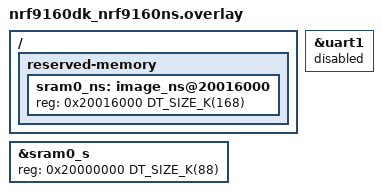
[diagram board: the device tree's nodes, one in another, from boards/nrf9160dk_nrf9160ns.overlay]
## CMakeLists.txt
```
#
# Copyright (c) 2021 Linaro Limited
#
# SPDX-License-Identifier: Apache-2.0
#

# Building TFM requires Cmake 3.15.
cmake_minimum_required(VERSION 3.15)

find_package(Zephyr REQUIRED HINTS $ENV{ZEPHYR_BASE})

project(psa_custom_service)

target_sources(app PRIVATE src/main.c)
target_sources(app PRIVATE src/util_app_log.c)
target_sources(app PRIVATE src/util_sformat.c)

target_include_directories(app PRIVATE
  ${ZEPHYR_TRUSTED_FIRMWARE_M_MODULE_DIR}/trusted-firmware-m/interface/include
)

# In TF-M, for release build, all the logs are silenced. At least enable
# `LOG_LEVEL_INFO`
set_property(TARGET zephyr_property_target
             APPEND PROPERTY TFM_CMAKE_OPTIONS
             -DTFM_SPM_LOG_LEVEL=TFM_SPM_LOG_LEVEL_INFO
             -DTFM_PARTITION_LOG_LEVEL=TFM_PARTITION_LOG_LEVEL_INFO
)
```

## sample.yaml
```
sample:
  description: PSA Custom Service sample
  name: PSA Custom Service
tests:
    sample.psa_custom_service:
        tags: introduction tfm psa custom service
        platform_allow: mps2_an521_nonsecure lpcxpresso55s69_ns nrf5340dk_nrf5340_cpuappns
          nrf9160dk_nrf9160ns nucleo_l552ze_q_ns v2m_musca_s1_nonsecure stm32l562e_dk_ns
          bl5340_dvk_cpuappns
        harness: console
        harness_config:
          type: multi_line
          regex:
            - "app: Hashing the message"
            - "\\[Example partition\\] Calculating SHA-256 hash!"
            - "\\[Example partition\\] Done!"
            - "app: Size of SHA-256 hash is 32 bytes"
```

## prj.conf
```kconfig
#
# Copyright (c) 2021 Linaro Limited
#
# SPDX-License-Identifier: Apache-2.0
#

CONFIG_LOG=y
CONFIG_LOG_RUNTIME_FILTERING=y
CONFIG_LOG_BUFFER_SIZE=2048
CONFIG_LOG_PROCESS_TRIGGER_THRESHOLD=0
CONFIG_LOG_DEFAULT_LEVEL=4

CONFIG_BUILD_WITH_TFM=y
CONFIG_TFM_IPC=y
CONFIG_TFM_PARTITION_EXAMPLE=y
# CONFIG_TFM_ISOLATION_LEVEL=3
# CONFIG_TFM_BL2=y
# CONFIG_TFM_CMAKE_BUILD_TYPE_DEBUG=y

# The Zephyr CMSIS emulation assumes that ticks are ms, currently
CONFIG_SYS_CLOCK_TICKS_PER_SEC=1000

CONFIG_MAIN_STACK_SIZE=4096
CONFIG_HEAP_MEM_POOL_SIZE=4096
```

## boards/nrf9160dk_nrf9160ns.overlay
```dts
/*
 * Copyright (c) 2020 Nordic Semiconductor ASA.
 *
 * SPDX-License-Identifier: Apache-2.0
 */

/* Modify the SRAM partitioning to accommodate the requirements
 * for the Secure (TF-M) firmware for the configuration that is
 * used in this sample.
 */

/* Increase the size of the Secure Firmware (TF-M).
 * This modification is not required at the moment,
 * since TF-M region definitions are configured
 * statically in the TF-M project.
 */
&sram0_s {
	reg = <0x20000000 DT_SIZE_K(88)>;
};

/* Decrease the size of the Non-Secure Firmware (Zephyr),
 * and move its starting address to the offset expected by
 * TF-M.
 */
/delete-node/ &sram0_ns;
/ {
	reserved-memory {
		sram0_ns: image_ns@20016000 {
			reg = <0x20016000 DT_SIZE_K(168)>;
		};
	};
};

/* Disable UART1, because it is used by default in TF-M */
&uart1 {
	status = "disabled";
};
```

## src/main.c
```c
/*
 * Copyright (c) 2021 Linaro Limited
 *
 * SPDX-License-Identifier: Apache-2.0
 */

#include <zephyr.h>
#include <logging/log_ctrl.h>
#include <logging/log.h>

#include "tfm_example_partition_api.h"
#include "util_app_log.h"
#include "util_sformat.h"

/** Declare a reference to the application logging interface. */
LOG_MODULE_DECLARE(app, CONFIG_LOG_DEFAULT_LEVEL);

struct sf_hex_tbl_fmt main_fmt = {
	.ascii = true,
	.addr_label = true,
	.addr = 0
};

void main(void)
{
	/* Message to be hashed */
	uint8_t input[] = "Please hash this message.";
	uint8_t hash[PSA_HASH_SIZE(PSA_ALG_SHA_256)] = { 0 };
	size_t hash_len;
	psa_status_t status;

	/* Initialise the logger subsys and dump the current buffer. */
	log_init();

	LOG_INF("Hashing the message");
	al_dump_log();

	/* Display the message */
	sf_hex_tabulate_16(&main_fmt, input, strlen(input));

	status = al_psa_status(
		psa_example_hash(input,
						 strlen(input),
						 hash,
						 sizeof(hash),
						 &hash_len),
		__func__);

	if (status != PSA_SUCCESS) {
		LOG_ERR("Failed to compute SHA-256 hash");
		goto err;
	}

	LOG_INF("Size of SHA-256 hash is %d bytes", hash_len);
	al_dump_log();

	/* Display the SHA-256 hash */
	sf_hex_tabulate_16(&main_fmt, hash, (size_t)(PSA_HASH_SIZE(PSA_ALG_SHA_256)));

err:
	/* Dump any queued log messages, and wait for system events. */
	al_dump_log();
}
```

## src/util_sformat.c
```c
/*
 * Copyright (c) 2019,2020 Linaro Limited
 *
 * SPDX-License-Identifier: Apache-2.0
 */

#include <ctype.h>
#include <stdio.h>
#include "util_sformat.h"

static void sf_hex_ascii(unsigned char *data, size_t len, unsigned char nonvis)
{
	uint32_t idx;

	/* Render printable characters. */
	idx = 0;
	while (len) {
		printf("%c", isprint(data[idx]) ? data[idx] : nonvis);
		idx++;
		len--;
	}
}

void sf_hex_tabulate_16(struct sf_hex_tbl_fmt *fmt, unsigned char *data,
			size_t len)
{
	uint32_t idx;
	uint32_t cpos;     /* Current position. */
	uint32_t ca;       /* Current address. */
	uint32_t ea;       /* End address. */

	if (!len) {
		return;
	}

	/* Set the end address (since we modify len in the write loop). */
	ea = fmt->addr + len;

	/* Check if we need to render the top address bar. */
	if (fmt->addr_label) {
		/* Render the top address bar. */
		printf("\n");
		printf("          ");
		printf("0  1  2  3  4  5  6  7  8  9  ");
		printf("A  B  C  D  E  F\n");
		printf("%08X ", fmt->addr - (fmt->addr % 16));
	}

	/* Insert offset padding for first row if necessary. */
	cpos = fmt->addr % 16;
	if (cpos != 0) {
		for (idx = 0; idx < cpos; idx++) {
			printf("   ");
		}
	}

	/* Print data row by row. */
	idx = 0;
	ca = fmt->addr;
	while (len) {
		/* Print the current value. */
		printf("%02X ", data[idx++]);
		cpos++;
		ca++;

		/* Wrap around to the next line if necessary. */
		if (cpos == 16 || ca == ea) {
			/* Render ASCII equiv at end of row if requested. */
			if (fmt->ascii) {
				if (ca == ea) {
					/* Handle last/single row. */
					if (ca % 16) {
						/* PARTIAL row (< 16 vals). */
						printf("%.*s",
							   (16 - ca % 16) * 3,
							   "                "
							   "                "
							   "                ");
						sf_hex_ascii(
							&data[idx - (ca % 16)],
							ca - fmt->addr < 16 ?
							idx % 16 : ca % 16,
							'.');
					} else {
						/* FULL row. */
						sf_hex_ascii(
							&data[idx - 16],
							16, '.');
					}
				} else if (ca < fmt->addr + 15) {
					/* Handle first row. */
					printf("%.*s", fmt->addr % 16,
						   "                ");
					sf_hex_ascii(data,
							 16 - fmt->addr % 16, '.');
				} else {
					/* Full row. */
					sf_hex_ascii(&data[idx - 16], 16, '.');
				}
			}

			/* Wrap around if this isn't the last row. */
			printf("\n");
			if (ca != ea) {
				/* Render the next base row addr. */
				if (fmt->addr_label) {
					printf("%08X ", ca);
				}
			}
			cpos = 0;
		}
		len--;
	}
	printf("\n");
}
```

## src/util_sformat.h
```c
/*
 * Copyright (c) 2019,2020 Linaro Limited
 *
 * SPDX-License-Identifier: Apache-2.0
 */

#ifndef _SFORMAT_H_
#define _SFORMAT_H_

#include <stdint.h>
#include <zephyr.h>

#ifdef __cplusplus
extern "C" {
#endif

/**
 * @brief Indicates how hex data should be rendered in tabular format.
 */
struct sf_hex_tbl_fmt {
	/** Whether or not to render ASCII equivalents. */
	uint8_t ascii : 1;
	/** Whether or not to add address labels to the output. */
	uint8_t addr_label : 1;
	/** The starting value for the address labels. */
	uint32_t addr;
} __packed;

/**
 * @brief Prints a 16-value wide tabular rendering of 8-bit hex data, with
 *        optional ascii equivalents and address labels.
 *
 * @param fmt   Pointer to thee sf_hex_tbl_fmt struct indicating how the
 *              table should be rendered.
 * @param data  Pointer to the data to render.
 * @param len   The number of bytes to render from data.
 */
void sf_hex_tabulate_16(struct sf_hex_tbl_fmt *fmt, unsigned char *data,
			size_t len);

#ifdef __cplusplus
}
#endif

#endif /* _SFORMAT_H_ */
```
